# ATSAMC20J17AU device description
Architecture: CORTEX-M0PLUS; Family: SAMC; Series: SAMC20
Registers are 32-bit, read-write, reset 0x0 unless marked. A register's access mark holds for its fields unless they carry their own. Offsets are from the block's base; [hi:lo] are bit positions; lines under a group give offsets from that group; {n}, {i} and the like mark numbered series; 'fields as' and 'values as' point back to an identical list.

## PM — Power Manager
Instances: PM 0x40000400
0x01 SLEEPCFG 8-bit — Sleep Configuration
  [2:0] SLEEPMODE
    2=IDLE (CPU, AHBx, and APBx clocks are OFF); 4=STANDBY (All Clocks are OFF)
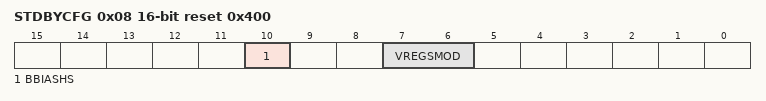
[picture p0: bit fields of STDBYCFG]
0x08 STDBYCFG 16-bit reset 0x400 — Standby Configuration
  [10] BBIASHS — Back Bias for HMCRAMCHS
  [7:6] VREGSMOD — Voltage Regulator Standby mode
    0=AUTO (Automatic mode); 1=PERFORMANCE (Performance oriented); 2=LP (Low Power oriented)
Value list PM_STDBYCFG__LINKPD: 0=DEFAULT (Power domains are not linked); 1=PD01 (PD0 and PD1 power domains are linked); 2=PD12 (PD1 and PD2 power domains are linked); 3=PD012 (All power domains are linked)
Value list PM_STDBYCFG__PDCFG: 0=DEFAULT (All power domains switching is handled by hardware.); 1=PD0 (PD0 is forced ACTIVE. PD1 and PD2 power domains switching is handled by hardware.); 2=PD01 (PD0 and PD1 are forced ACTIVE. PD2 power domain switching is handled by hardware.); 3=PD012 (All power domains are forced ACTIVE.)

## PORT — Port Module
Instances: PORT 0x41000000, PORT_IOBUS 0x60000000
{0x0+0x80*i} GROUP[{i}] (i=0..1) group
  0x00 DIR — Data Direction
  0x04 DIRCLR (atomic clear of DIR) — Data Direction Clear
  0x08 DIRSET (atomic set of DIR) — Data Direction Set
  0x0C DIRTGL (atomic toggle of DIR) — Data Direction Toggle
  0x10 OUT — Data Output Value
  0x14 OUTCLR (atomic clear of OUT) — Data Output Value Clear
  0x18 OUTSET (atomic set of OUT) — Data Output Value Set
  0x1C OUTTGL (atomic toggle of OUT) — Data Output Value Toggle
  0x20 IN ro — Data Input Value
  0x24 CTRL — Control
    [31:0] SAMPLING — Input Sampling Mode
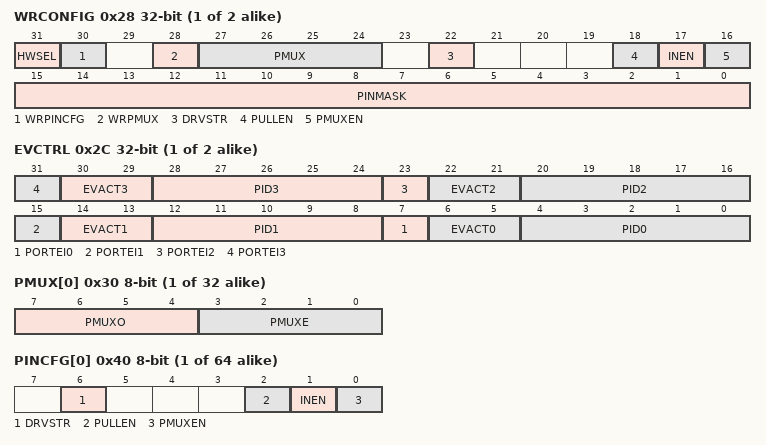
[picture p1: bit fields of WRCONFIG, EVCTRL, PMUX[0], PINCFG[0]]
  0x28 WRCONFIG wo — Write Configuration
    [31] HWSEL — Half-Word Select
    [30] WRPINCFG — Write PINCFG Registers
    [28] WRPMUX — Write PMUX Registers
    [27:24] PMUX — Peripheral Multiplexing Template
    [22] DRVSTR — Output Driver Strength Selection
    [18] PULLEN — Pull Enable
    [17] INEN — Input Enable
    [16] PMUXEN — Select Peripheral Multiplexer
    [15:0] PINMASK — Pin Mask for Multiple Pin Configuration
  0x2C EVCTRL — Event Input Control
    [8n+7] PORTEI{n} (n=0..3) — Port Event Enable Input {n}
    [30:29] EVACT3 — Port Event Action 3
    [8n+4:8n] PID{n} (n=0..3) — Port Event Pin Identifier {n}
    [22:21] EVACT2 — Port Event Action 2
    [14:13] EVACT1 — Port Event Action 1
    [6:5] EVACT0 — Port Event Action 0
      0=OUT (Event output to pin); 1=SET (Set output register of pin on event); 2=CLR (Clear output register of pin on event); 3=TGL (Toggle output register of pin on event)
  {0x30+j} PMUX[{j}] (j=0..15) 8-bit — Peripheral Multiplexing n
    [7:4] PMUXO — Peripheral Multiplexing for Odd-Numbered Pin
      0=A (Peripheral function A selected); 1=B (Peripheral function B selected); 2=C (Peripheral function C selected); 3=D (Peripheral function D selected); 4=E (Peripheral function E selected); 5=F (Peripheral function F selected); 6=G (Peripheral function G selected); 7=H (Peripheral function H selected); 8=I (Peripheral function I selected)
    [3:0] PMUXE — Peripheral Multiplexing for Even-Numbered Pin
      values as PMUXO
  {0x40+j} PINCFG[{j}] (j=0..31) 8-bit — Pin Configuration n
    [6] DRVSTR — Output Driver Strength Selection
    [2] PULLEN — Pull Enable
    [1] INEN — Input Enable
    [0] PMUXEN — Select Peripheral Multiplexer

## RSTC — Reset Controller
Instances: RSTC 0x40000C00
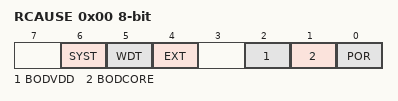
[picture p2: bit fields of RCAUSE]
0x00 RCAUSE 8-bit ro reset not defined — Reset Cause
  [6] SYST — System Reset Request
  [5] WDT — Watchdog Reset
  [4] EXT — External Reset
  [2] BODVDD — Brown Out VDD Detector Reset
  [1] BODCORE — Brown Out CORE Detector Reset
  [0] POR — Power On Reset

## SUPC — Supply Controller
Instances: SUPC 0x40001800
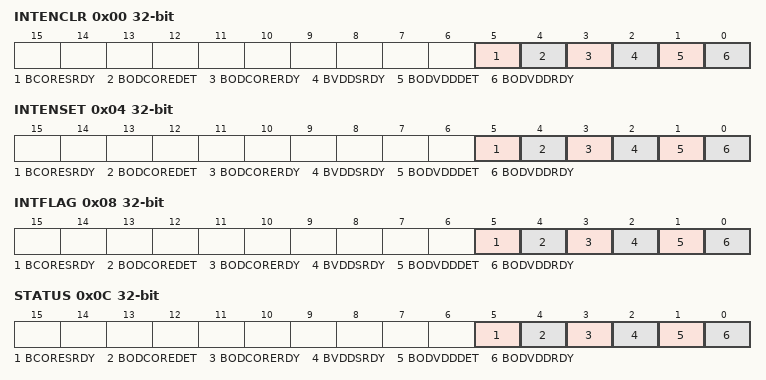
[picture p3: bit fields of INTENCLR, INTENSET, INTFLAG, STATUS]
0x00 INTENCLR (atomic clear) — Interrupt Enable Clear
  [5] BCORESRDY — BODCORE Synchronization Ready
  [4] BODCOREDET — BODCORE Detection
  [3] BODCORERDY — BODCORE Ready
  [2] BVDDSRDY — BODVDD Synchronization Ready
  [1] BODVDDDET — BODVDD Detection
  [0] BODVDDRDY — BODVDD Ready
0x04 INTENSET (atomic set) — Interrupt Enable Set
  fields as INTENCLR
0x08 INTFLAG (atomic clear) — Interrupt Flag Status and Clear
  fields as INTENCLR
0x0C STATUS ro — Power and Clocks Status
  fields as INTENCLR
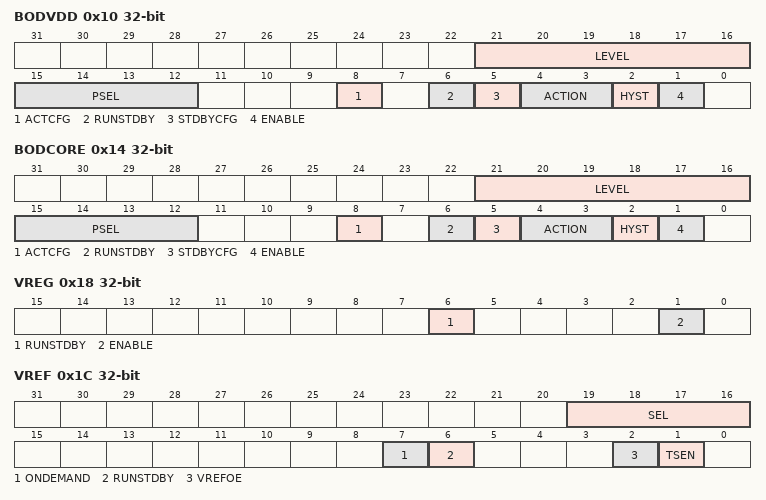
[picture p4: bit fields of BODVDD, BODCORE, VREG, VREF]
0x10 BODVDD (WSYNC) — BODVDD Control
  [21:16] LEVEL — Threshold Level for VDD
  [15:12] PSEL — Prescaler Select
    0=DIV2 (Divide clock by 2); 1=DIV4 (Divide clock by 4); 2=DIV8 (Divide clock by 8); 3=DIV16 (Divide clock by 16); 4=DIV32 (Divide clock by 32); 5=DIV64 (Divide clock by 64); 6=DIV128 (Divide clock by 128); 7=DIV256 (Divide clock by 256); 8=DIV512 (Divide clock by 512); 9=DIV1024 (Divide clock by 1024); 10=DIV2048 (Divide clock by 2048); 11=DIV4096 (Divide clock by 4096); 12=DIV8192 (Divide clock by 8192); 13=DIV16384 (Divide clock by 16384); 14=DIV32768 (Divide clock by 32768); 15=DIV65536 (Divide clock by 65536)
  [8] ACTCFG — Configuration in Active mode
  [6] RUNSTDBY — Run during Standby
  [5] STDBYCFG — Configuration in Standby mode
  [4:3] ACTION — Action when Threshold Crossed
    0=NONE (No action); 1=RESET (The BODVDD generates a reset); 2=INT (The BODVDD generates an interrupt)
  [2] HYST — Hysteresis Enable
  [1] ENABLE
0x14 BODCORE (WSYNC) — BODCORE Control
  [21:16] LEVEL — Threshold Level
  [15:12] PSEL — Prescaler Select
    values as BODVDD.PSEL
  [8] ACTCFG — Configuration in Active mode
  [6] RUNSTDBY — Run during Standby
  [5] STDBYCFG — Configuration in Standby mode
  [4:3] ACTION — Action when Threshold Crossed
    0=NONE (No action); 1=RESET (The BODCORE generates a reset); 2=INT (The BODCORE generates an interrupt)
  [2] HYST — Hysteresis Enable
  [1] ENABLE
0x18 VREG — VREG Control
  [6] RUNSTDBY — Run during Standby
  [1] ENABLE
0x1C VREF — VREF Control
  [19:16] SEL — Voltage Reference Selection
    0=1V024 (1.024V voltage reference typical value); 2=2V048 (2.048V voltage reference typical value); 3=4V096 (4.096V voltage reference typical value)
  [7] ONDEMAND — On Demand Contrl
  [6] RUNSTDBY — Run during Standby
  [2] VREFOE — Voltage Reference Output Enable
  [1] TSEN — Temperature Sensor Output Enable

## Notices in the file
Copyright (c) 2018 Microchip Technology Inc.
SPDX-License-Identifier: Apache-2.0
Licensed under the Apache License, Version 2.0 (the "License");
you may not use this file except in compliance with the License.
You may obtain a copy of the License at
http://www.apache.org/licenses/LICENSE-2.0
Unless required by applicable law or agreed to in writing, software
distributed under the License is distributed on an "AS IS" BASIS,
WITHOUT WARRANTIES OR CONDITIONS OF ANY KIND, either express or implied.
See the License for the specific language governing permissions and
limitations under the License.
